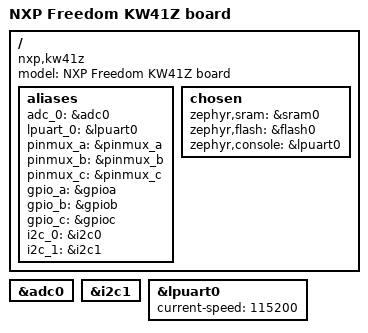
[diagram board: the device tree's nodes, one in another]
/dts-v1/;

#include <nxp/nxp_kw41z.dtsi>

/ {
	model = "NXP Freedom KW41Z board";
	compatible = "nxp,kw41z", "nxp,mkw41z4";

	aliases {
		adc_0 = &adc0;
		lpuart_0 = &lpuart0;
		pinmux_a = &pinmux_a;
		pinmux_b = &pinmux_b;
		pinmux_c = &pinmux_c;
		gpio_a = &gpioa;
		gpio_b = &gpiob;
		gpio_c = &gpioc;
		i2c_0 = &i2c0;
		i2c_1 = &i2c1;
	};

	chosen {
		zephyr,sram = &sram0;
		zephyr,flash = &flash0;
		zephyr,console = &lpuart0;
	};
};

&adc0 {
	status = "ok";
};

&i2c1 {
	status = "ok";
};

&lpuart0 {
	status = "ok";
	current-speed = <115200>;
};
